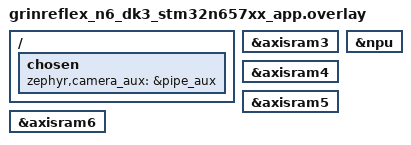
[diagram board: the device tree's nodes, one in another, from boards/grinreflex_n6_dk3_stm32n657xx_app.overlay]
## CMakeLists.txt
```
cmake_minimum_required(VERSION 3.20.0)

find_package(Zephyr REQUIRED HINTS $ENV{ZEPHYR_BASE})
project(gf_n6_npu)

target_include_directories(app PRIVATE
include
)

target_sources(app PRIVATE
    src/main.c
    src/model.c
)
```

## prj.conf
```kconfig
CONFIG_STM32_NPU=y
CONFIG_YOLOV8_OBJ_DET=y

CONFIG_LOG_DEFAULT_LEVEL=3

#CONFIG_FAULT_DUMP=2
CONFIG_ASSERT=y
#CONFIG_RESET_ON_FATAL_ERROR=n
#CONFIG_LOG=y

CONFIG_HW_STACK_PROTECTION=y   # if supported
CONFIG_STACK_SENTINEL=y
CONFIG_INIT_STACKS=y

CONFIG_MAIN_STACK_SIZE=65536

CONFIG_CPP=y
CONFIG_STD_CPP20=y
CONFIG_CPP_EXCEPTIONS=y
CONFIG_CPP_RTTI=y

CONFIG_REQUIRES_FULL_LIBC=y
CONFIG_GLIBCXX_LIBCPP=y

CONFIG_NEWLIB_LIBC=y
CONFIG_PICOLIBC=n

CONFIG_COMMON_LIBC_MALLOC=y
CONFIG_HEAP_MEM_POOL_SIZE=8192

CONFIG_POSIX_API=y

CONFIG_ASSERT_VERBOSE=y

CONFIG_FAULT_DUMP=2

CONFIG_DMA_LOG_LEVEL_DBG=y

# Video / DCMI logs
CONFIG_VIDEO_LOG_LEVEL_DBG=y


CONFIG_VIDEO_LOG_LEVEL_DBG=y
CONFIG_VIDEO_LOG_LEVEL_INF=y

CONFIG_VIDEO_BUFFER_POOL_NUM_MAX=4
CONFIG_VIDEO_STM32_DCMIPP_SENSOR_WIDTH=320
CONFIG_VIDEO_STM32_DCMIPP_SENSOR_HEIGHT=240
CONFIG_VIDEO_STM32_DCMIPP_SENSOR_PIXEL_FORMAT="RGBP"

CONFIG_MULTI_HEAP=y
CONFIG_CPU_LOAD=y
CONFIG_MEM_ATTR_HEAP=y
# To be sure LOGGER can still ouput message move this one priority level above main thread
CONFIG_LOG_PROCESS_THREAD_CUSTOM_PRIORITY=y
CONFIG_LOG_PROCESS_THREAD_PRIORITY=13
CONFIG_LV_FONT_MONTSERRAT_8=y

#CONFIG_USE_STM32_MW_ISP=y
CONFIG_DYNAMIC_INTERRUPTS=y

CONFIG_CACHE_MANAGEMENT=y
CONFIG_ICACHE=y
CONFIG_DCACHE=y
```

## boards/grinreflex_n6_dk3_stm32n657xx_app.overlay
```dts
/*
 * Copyright (c) 2025 STMicroelectronics.
 * All rights reserved.
 *
 * This software is licensed under terms that can be found in the LICENSE file
 * in the root directory of this software component.
 * If no LICENSE file comes with this software, it is provided AS-IS.
 */

/ {
	chosen {
		zephyr,camera_aux = &pipe_aux;
	};
};

// Turn on so called npu rams. They will used by NPU for model actvation buffers
&axisram3 {
	status = "okay";
};
&axisram4 {
	status = "okay";
};
&axisram5 {
	status = "okay";
};
&axisram6 {
	status = "okay";
};

// Turn on npu
&npu {
	status = "okay";
};
```

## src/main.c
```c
/**
 ******************************************************************************
 * @file    main.c
 * @author  GPM Application Team
 *
 ******************************************************************************
 * @attention
 *
 * Copyright (c) 2025 STMicroelectronics.
 * All rights reserved.
 *
 * This software is licensed under terms that can be found in the LICENSE file
 * in the root directory of this software component.
 * If no LICENSE file comes with this software, it is provided AS-IS.
 *
 ******************************************************************************
 */

#include <zephyr/debug/cpu_load.h>
#include <zephyr/drivers/display.h>
#include <zephyr/drivers/video.h>
#include <zephyr/kernel.h>
#include <zephyr/logging/log.h>
#include <zephyr/sys/__assert.h>
#include <zephyr/sys/util.h>

#include <font/lv_font.h>
#include <lvgl.h>

#include <stdarg.h>

#include "model.h"

LOG_MODULE_REGISTER(main, LOG_LEVEL_INF);

// #define DISPLAY_WIDTH DT_PROP(DT_CHOSEN(zephyr_display), width)
// #define DISPLAY_HEIGHT DT_PROP(DT_CHOSEN(zephyr_display), height)
#define DISPLAY_WIDTH 224
#define DISPLAY_HEIGHT 224
#define DISPLAY_BPP 2

#define NN_WIDTH CONFIG_NPU_WIDTH
#define NN_HEIGHT CONFIG_NPU_HEIGHT
#define NN_BPP 3
#define NPU_BUFFER_POOL_ALIGN 32

static struct k_thread nn_thread;
static K_THREAD_STACK_DEFINE(nn_thread_stack, 4096);

static int display_setup(const struct device *const display_dev) {
  int ret;

  ret = display_set_pixel_format(display_dev, PIXEL_FORMAT_RGB_565);
  if (ret) {
    LOG_INF("Failed: display_set_pixel_format ret = %d", ret);
  }

  ret = display_blanking_off(display_dev);
  __ASSERT_NO_MSG(ret == 0);

  return 0;
}

static void print_text(lv_layer_t *layer, int x, int y, lv_text_align_t align,
                       char *fmt, ...) {
  lv_draw_label_dsc_t tdsc;
  char text_buffer[128];
  lv_area_t coords;
  va_list ap;

  va_start(ap, fmt);
  vsnprintf(text_buffer, sizeof(text_buffer), fmt, ap);

  /* shadow */
  lv_draw_label_dsc_init(&tdsc);
  tdsc.color = lv_color_make(16, 16, 16);
  tdsc.font = &lv_font_montserrat_8;
  coords.x1 = x + 1;
  coords.y1 = y + 1;
  coords.x2 = DISPLAY_WIDTH;
  coords.y2 = DISPLAY_HEIGHT;
  tdsc.text = text_buffer;
  tdsc.text_local = 1;
  tdsc.align = align;
  lv_draw_label(layer, &tdsc, &coords);

  /* text */
  tdsc.color = lv_color_make(255, 255, 255);
  coords.x1 = x;
  coords.y1 = y;
  lv_draw_label(layer, &tdsc, &coords);
  va_end(ap);
}

static void decorate_canvas(lv_obj_t *canvas) {
  int latest_inference_time = model_get_latest_inference_time();
  const lv_font_t *font = &lv_font_montserrat_8;
  lv_draw_rect_dsc_t rdsc;
  struct dbox boxes[10];
  lv_area_t coords;
  lv_layer_t layer;
  struct dbox *b;
  uint32_t ver;
  int load;
  int nb;
  int i;

  ver = sys_kernel_version_get();
  nb = model_get_boxes(boxes, ARRAY_SIZE(boxes));

  lv_canvas_init_layer(canvas, &layer);
  /* Draw banner */
  print_text(&layer, 0, 0, LV_TEXT_ALIGN_LEFT, "People Detection demo");
  print_text(&layer, 0, font->line_height, LV_TEXT_ALIGN_LEFT,
             "Powered by zephyr OS %d.%d.%d", SYS_KERNEL_VER_MAJOR(ver),
             SYS_KERNEL_VER_MINOR(ver), SYS_KERNEL_VER_PATCHLEVEL(ver));

  /* Draw inference time */
  print_text(&layer, 0, font->line_height * 2, LV_TEXT_ALIGN_LEFT,
             "Inference %d ms", latest_inference_time);
  latest_inference_time = latest_inference_time ? latest_inference_time : 1;
  print_text(&layer, 0, font->line_height * 3, LV_TEXT_ALIGN_LEFT,
             "Fps       %d", 1000 / latest_inference_time);
#ifdef CONFIG_CPU_LOAD
  load = cpu_load_get(1);
  print_text(&layer, 0, font->line_height * 4, LV_TEXT_ALIGN_LEFT,
             "cpu load  %d.%d%%", load / 10, load % 10);
#else
  (void)load;
#endif

  /* Draw boxes */
  lv_draw_rect_dsc_init(&rdsc);
  rdsc.border_color = lv_palette_main(LV_PALETTE_RED);
  rdsc.border_width = 8;
  rdsc.radius = 10;
  rdsc.bg_opa = 0;
  for (i = 0; i < nb; i++) {
    b = &boxes[i];
    coords.x1 = b->x;
    coords.y1 = b->y;
    coords.x2 = b->x + b->w;
    coords.y2 = b->y + b->h;
    lv_draw_rect(&layer, &rdsc, &coords);
  }

  lv_canvas_finish_layer(canvas, &layer);
}

static int video_crop_setup(const struct device *const video_dev,
                            uint32_t sensor_width, uint32_t sensor_height) {
  const float ratioy = (float)sensor_height / DISPLAY_HEIGHT;
  const float ratiox = (float)sensor_width / DISPLAY_WIDTH;
  const float ratio = MIN(ratiox, ratioy);
  struct video_selection crop = {
      .type = VIDEO_BUF_TYPE_OUTPUT,
  };
  int ret;

  __ASSERT_NO_MSG(ratio >= 1);
  __ASSERT_NO_MSG(ratio < 64);

  crop.target = VIDEO_SEL_TGT_CROP;
  crop.rect.width = DISPLAY_WIDTH * ratio;
  crop.rect.height = DISPLAY_HEIGHT * ratio;
  crop.rect.left = (sensor_width - crop.rect.width + 1) / 2;
  crop.rect.top = (sensor_height - crop.rect.height + 1) / 2;

  ret = video_set_selection(video_dev, &crop);
  __ASSERT_NO_MSG(ret == 0);

  return 0;
}

static int video_resize_setup(const struct device *const video_dev,
                              uint32_t width, uint32_t height) {
  struct video_selection comp = {
      .type = VIDEO_BUF_TYPE_OUTPUT,
  };
  int ret;

  LOG_INF("video_resize_setup: %d x %d", width, height);

  comp.target = VIDEO_SEL_TGT_COMPOSE;
  comp.rect.left = 0;
  comp.rect.top = 0;
  comp.rect.width = width;
  comp.rect.height = height;

  ret = video_set_selection(video_dev, &comp);
  __ASSERT_NO_MSG(ret == 0);

  return 0;
}

static int video_alloc_and_queue_buffers(const struct device *const video_dev,
                                         size_t bsize, int align) {
  struct video_buffer *buffers[2];
  int ret;
  int i;

  for (i = 0; i < ARRAY_SIZE(buffers); i++) {
    buffers[i] = video_buffer_aligned_alloc(bsize, align, K_FOREVER);
    __ASSERT_NO_MSG(buffers[i]);
    buffers[i]->type = VIDEO_BUF_TYPE_OUTPUT;
    ret = video_enqueue(video_dev, buffers[i]);
    __ASSERT_NO_MSG(ret == 0);
    LOG_INF("buffer %p(%p) queue to %s pipe", (void *)buffers[i],
            (void *)buffers[i]->buffer, video_dev->name);
  }

  return 0;
}

static int video_main_setup(const struct device *const video_dev,
                            uint32_t sensor_width, uint32_t sensor_height) {
  struct video_format fmt;
  size_t bsize;
  int ret;

  /* setup crop, compose and output */
  ret = video_crop_setup(video_dev, sensor_width, sensor_height);
  __ASSERT_NO_MSG(ret == 0);
  ret = video_resize_setup(video_dev, DISPLAY_WIDTH, DISPLAY_HEIGHT);
  __ASSERT_NO_MSG(ret == 0);
  fmt.pixelformat = VIDEO_FOURCC_FROM_STR("RGBP");
  fmt.width = DISPLAY_WIDTH;
  fmt.height = DISPLAY_HEIGHT;
  fmt.pitch = fmt.width * DISPLAY_BPP;
  ret = video_set_format(video_dev, &fmt);
  __ASSERT_NO_MSG(ret == 0);

  /* alloc buffers and queue them */
  bsize = fmt.pitch * fmt.height;
  ret = video_alloc_and_queue_buffers(video_dev, bsize,
                                      CONFIG_VIDEO_BUFFER_POOL_ALIGN);
  __ASSERT_NO_MSG(ret == 0);

  return 0;
}

static int video_aux_setup(const struct device *const video_dev,
                           uint32_t sensor_width, uint32_t sensor_height) {
  struct video_format fmt;
  size_t bsize;
  int ret;

  /* setup crop, compose and output */
  ret = video_crop_setup(video_dev, sensor_width, sensor_height);
  __ASSERT_NO_MSG(ret == 0);
  ret = video_resize_setup(video_dev, NN_WIDTH, NN_HEIGHT);
  __ASSERT_NO_MSG(ret == 0);
  fmt.pixelformat = VIDEO_FOURCC_FROM_STR("RGB3");
  fmt.width = NN_WIDTH;
  fmt.height = NN_HEIGHT;
  fmt.pitch = fmt.width * NN_BPP;
  ret = video_set_format(video_dev, &fmt);
  __ASSERT_NO_MSG(ret == 0);

  /* alloc buffers and queue them */
  bsize = fmt.pitch * fmt.height;
  ret = video_alloc_and_queue_buffers(video_dev, bsize, NPU_BUFFER_POOL_ALIGN);
  __ASSERT_NO_MSG(ret == 0);

  return 0;
}

static int video_setup(const struct device *const main_dev,
                       const struct device *const aux_dev) {
  struct video_format fmt;
  uint32_t sensor_height;
  uint32_t sensor_width;
  int ret;

  /* get default format to get sensor width / height */
  ret = video_get_format(main_dev, &fmt);
  __ASSERT_NO_MSG(ret == 0);
  sensor_height = fmt.height;
  sensor_width = fmt.width;

  LOG_INF("Default format: %dx%d", sensor_width, sensor_height);

  ret = video_main_setup(main_dev, sensor_width, sensor_height);
  __ASSERT_NO_MSG(ret == 0);

  ret = video_aux_setup(aux_dev, sensor_width, sensor_height);
  __ASSERT_NO_MSG(ret == 0);

  return 0;
}

int main() {
  const struct device *const camera_aux_dev =
      DEVICE_DT_GET(DT_CHOSEN(zephyr_camera_aux));
  const struct device *const display_dev =
      DEVICE_DT_GET(DT_CHOSEN(zephyr_display));
  const struct device *const video_dev =
      DEVICE_DT_GET(DT_CHOSEN(zephyr_camera));
  struct video_buffer *vbuf;
  lv_obj_t *canvas;
  k_tid_t nn_tid;
  int ret;

  __ASSERT_NO_MSG(device_is_ready(video_dev));
  __ASSERT_NO_MSG(device_is_ready(camera_aux_dev));
  __ASSERT_NO_MSG(device_is_ready(display_dev));

  /* move main thread priority to lowest one so we let others thread a chance to
   * run */
  k_thread_priority_set(k_current_get(), K_LOWEST_APPLICATION_THREAD_PRIO);

  /* create thread for nn process */
  nn_tid = k_thread_create(
      &nn_thread, nn_thread_stack, K_THREAD_STACK_SIZEOF(nn_thread_stack),
      model_thread_ep, (void *)camera_aux_dev, NULL, NULL, 0, 0, K_NO_WAIT);
  __ASSERT_NO_MSG(nn_tid);

  /* Configure display */
  ret = display_setup(display_dev);
  __ASSERT_NO_MSG(ret == 0);

  /* Configure video pipe */
  ret = video_setup(video_dev, camera_aux_dev);
  __ASSERT_NO_MSG(ret == 0);

  /* Start main pipe */
  LOG_INF("Starting main pipe");
  ret = video_stream_start(video_dev, VIDEO_BUF_TYPE_OUTPUT);
  __ASSERT_NO_MSG(ret == 0);

  LOG_INF("Starting aux pipe");
  ret = video_stream_start(camera_aux_dev, VIDEO_BUF_TYPE_OUTPUT);
  __ASSERT_NO_MSG(ret == 0);

  LOG_INF("STARTING");

  canvas = lv_canvas_create(lv_scr_act());
  while (1) {
    ret = video_dequeue(video_dev, &vbuf, K_FOREVER);
    __ASSERT_NO_MSG(ret == 0);

    lv_canvas_set_buffer(canvas, vbuf->buffer, DISPLAY_WIDTH, DISPLAY_HEIGHT,
                         LV_COLOR_FORMAT_RGB565);
    decorate_canvas(canvas);
    lv_timer_handler();

    ret = video_enqueue(video_dev, vbuf);
    __ASSERT_NO_MSG(ret == 0);
  }

  return 0;
}
```

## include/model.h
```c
/**
 ******************************************************************************
 * @file    model.h
 * @author  GPM Application Team
 *
 ******************************************************************************
 * @attention
 *
 * Copyright (c) 2025 STMicroelectronics.
 * All rights reserved.
 *
 * This software is licensed under terms that can be found in the LICENSE file
 * in the root directory of this software component.
 * If no LICENSE file comes with this software, it is provided AS-IS.
 *
 ******************************************************************************
 */


#ifndef __MODEL__
#define __MODEL__

struct dbox {
	/* upper left coord */
	int x;
	int y;
	int w;
	int h;
};

void model_thread_ep(void *arg1, void *arg2, void *arg3);
int model_get_boxes(struct dbox *boxes, int boxes_nb);
int model_get_latest_inference_time(void);

#endif
```

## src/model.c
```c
/**
 ******************************************************************************
 * @file    model.c
 * @author  GPM Application Team
 *
 ******************************************************************************
 * @attention
 *
 * Copyright (c) 2025 STMicroelectronics.
 * All rights reserved.
 *
 * This software is licensed under terms that can be found in the LICENSE file
 * in the root directory of this software component.
 * If no LICENSE file comes with this software, it is provided AS-IS.
 *
 ******************************************************************************
 */

#include "model.h"

#include <zephyr/cache.h>
#include <zephyr/drivers/video.h>
#include <zephyr/logging/log.h>
#include <zephyr/mem_mgmt/mem_attr_heap.h>

#include "ll_aton_rt_user_api.h"
#include "npu_cache.h"
#include "od_pp_loc.h"
#include "od_yolov8_pp_if.h"

// #define DISPLAY_WIDTH DT_PROP(DT_CHOSEN(zephyr_display), width)
// #define DISPLAY_HEIGHT DT_PROP(DT_CHOSEN(zephyr_display), height)

#define DISPLAY_WIDTH 224
#define DISPLAY_HEIGHT 224

/* post process conf */
#define AI_OD_YOLOV8_PP_CONF_THRESHOLD (0.5)
#define AI_OD_YOLOV8_PP_IOU_THRESHOLD (0.3)
#define AI_OD_YOLOV8_PP_MAX_BOXES_LIMIT (10)
#define AI_OD_YOLOV8_PP_NB_CLASSES (1)
#define AI_OD_YOLOV8_PP_TOTAL_BOXES (1029)

LOG_MODULE_REGISTER(model, LOG_LEVEL_INF);

LL_ATON_DECLARE_NAMED_NN_INSTANCE_AND_INTERFACE(yolov8_obj_det);

/* latest detections and associate mutex */
static od_pp_outBuffer_t pp_detections_buffer[AI_OD_YOLOV8_PP_TOTAL_BOXES];
static od_pp_outBuffer_t detections[AI_OD_YOLOV8_PP_MAX_BOXES_LIMIT];
static int detections_nb = -1;
static struct k_mutex boxes_lock;

static int latest_inference_time = 0;

static void Run_Inference(NN_Instance_TypeDef *network_instance) {
  LL_ATON_RT_RetValues_t ll_aton_rt_ret;

  do {
    /* Execute first/next step of Cube.AI/ATON runtime */
    ll_aton_rt_ret = LL_ATON_RT_RunEpochBlock(network_instance);
    /* Wait for next event */
    if (ll_aton_rt_ret == LL_ATON_RT_WFE)
      LL_ATON_OSAL_WFE();
  } while (ll_aton_rt_ret != LL_ATON_RT_DONE);

  LL_ATON_RT_Reset_Network(network_instance);
}

static void NPUCache_config() {
  npu_cache_init();
  npu_cache_enable();
}

static void model_npu_init() {
  NPUCache_config();

  LOG_INF("Npu subsystem ready");
}

static int clamp_point(int *x, int *y) {
  int xi = *x;
  int yi = *y;

  if (*x < 0)
    *x = 0;
  if (*y < 0)
    *y = 0;
  if (*x >= DISPLAY_WIDTH)
    *x = DISPLAY_WIDTH - 1;
  if (*y >= DISPLAY_HEIGHT)
    *y = DISPLAY_HEIGHT - 1;

  return (xi != *x) || (yi != *y);
}

static void convert_length(float32_t wi, float32_t hi, int *wo, int *ho) {
  *wo = (int)(DISPLAY_WIDTH * wi);
  *ho = (int)(DISPLAY_HEIGHT * hi);
}

static void convert_point(float32_t xi, float32_t yi, int *xo, int *yo) {
  *xo = (int)(DISPLAY_WIDTH * xi);
  *yo = (int)(DISPLAY_HEIGHT * yi);
}

static void model_detection_to_box(od_pp_outBuffer_t *d, struct dbox *b) {
  int xc, yc;
  int x0, y0;
  int x1, y1;
  int w, h;

  convert_point(d->x_center, d->y_center, &xc, &yc);
  convert_length(d->width, d->height, &w, &h);
  x0 = xc - (w + 1) / 2;
  y0 = yc - (h + 1) / 2;
  x1 = xc + (w + 1) / 2;
  y1 = yc + (h + 1) / 2;
  clamp_point(&x0, &y0);
  clamp_point(&x1, &y1);
  w = x1 - x0 + 1;
  h = y1 - y0 + 1;

  b->x = x0;
  b->y = y0;
  b->w = w;
  b->h = h;
}

void model_thread_ep(void *arg1, void *arg2, void *arg3) {
  const LL_Buffer_InfoTypeDef *nn_out_info =
      LL_ATON_Output_Buffers_Info_yolov8_obj_det();
  const LL_Buffer_InfoTypeDef *nn_in_info =
      LL_ATON_Input_Buffers_Info_yolov8_obj_det();
  const struct device *const camera_aux_dev = arg1;
  od_yolov8_pp_static_param_t pp_params;
  struct video_buffer *vbuf;
  od_yolov8_pp_in_centroid_t pp_input;
  od_pp_out_t pp_output;
  uint32_t nn_out_len;
  uint32_t nn_in_len;
  uint8_t *nn_out;
  uint32_t tick;
  int ret;
  int i;

  ret = k_mutex_init(&boxes_lock);
  __ASSERT_NO_MSG(ret == 0);
  detections_nb = 0;

  model_npu_init();

  /* Initialize Cube.AI/ATON ... */
  LL_ATON_RT_RuntimeInit();
  /* ... and model instance */
  LL_ATON_RT_Init_Network(&NN_Instance_yolov8_obj_det);

  nn_in_len = LL_Buffer_len(nn_in_info);
  nn_out_len = LL_Buffer_len(nn_out_info);
  nn_out = LL_Buffer_addr_start(nn_out_info);
  __ASSERT_NO_MSG(nn_out);

  /* pp init */
  pp_params.nb_classes = AI_OD_YOLOV8_PP_NB_CLASSES;
  pp_params.nb_total_boxes = AI_OD_YOLOV8_PP_TOTAL_BOXES;
  pp_params.max_boxes_limit = AI_OD_YOLOV8_PP_MAX_BOXES_LIMIT;
  pp_params.conf_threshold = AI_OD_YOLOV8_PP_CONF_THRESHOLD;
  pp_params.iou_threshold = AI_OD_YOLOV8_PP_IOU_THRESHOLD;
  pp_params.pScratchBuff = NULL;

  ret = od_yolov8_pp_reset(&pp_params);
  __ASSERT_NO_MSG(ret == 0);

  while (1) {
    ret = video_dequeue(camera_aux_dev, &vbuf, K_FOREVER);
    __ASSERT_NO_MSG(ret == 0);

    /* run inference */
    __ASSERT_NO_MSG(vbuf->bytesused == nn_in_len);
    /* setup input buffer. No need cache ops since full hw path DCMIPP -> NPU */
    ret = LL_ATON_Set_User_Input_Buffer_yolov8_obj_det(0, vbuf->buffer, nn_in_len);
    __ASSERT_NO_MSG(ret == LL_ATON_User_IO_NOERROR);
    /* setup output. Invalidate ouput so post-process access latest inference
     * result */
    ret = sys_cache_data_invd_range(nn_out, nn_out_len);
    __ASSERT_NO_MSG(ret == 0);
    /* let's go */
    tick = HAL_GetTick();
    Run_Inference(&NN_Instance_yolov8_obj_det);
    tick = HAL_GetTick() - tick;
    latest_inference_time = tick;

    ret = video_enqueue(camera_aux_dev, vbuf);
    __ASSERT_NO_MSG(ret == 0);

    /* post process */
    pp_input.pRaw_detections = (float32_t *)nn_out;
    pp_output.pOutBuff = pp_detections_buffer;
    ret = od_yolov8_pp_process(&pp_input, &pp_output, &pp_params);
    __ASSERT_NO_MSG(ret == 0);

    /* boxes state */
    ret = k_mutex_lock(&boxes_lock, K_FOREVER);
    __ASSERT_NO_MSG(ret == 0);

    detections_nb = pp_output.nb_detect;
    for (i = 0; i < pp_output.nb_detect; i++)
      detections[i] = pp_output.pOutBuff[i];

    ret = k_mutex_unlock(&boxes_lock);
    __ASSERT_NO_MSG(ret == 0);
  }
}

int model_get_boxes(struct dbox *boxes, int boxes_nb) {
  int nb = 0;
  int ret;
  int i;

  /* not yet init */
  if (detections_nb < 0)
    return 0;

  ret = k_mutex_lock(&boxes_lock, K_FOREVER);
  __ASSERT_NO_MSG(ret == 0);

  nb = MIN(boxes_nb, detections_nb);
  for (i = 0; i < nb; i++)
    model_detection_to_box(&detections[i], &boxes[i]);

  ret = k_mutex_unlock(&boxes_lock);
  __ASSERT_NO_MSG(ret == 0);

  return nb;
}

int model_get_latest_inference_time() { return latest_inference_time; }
```
